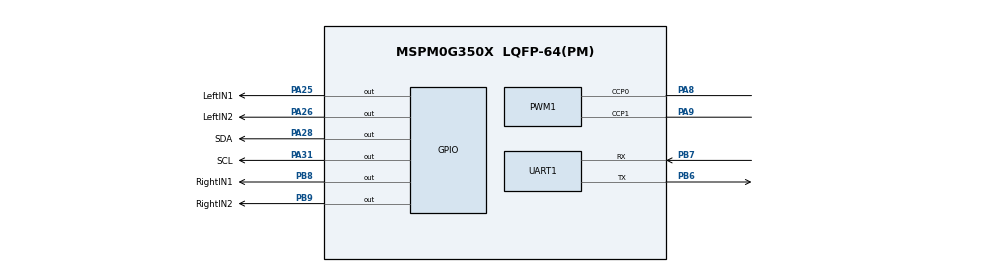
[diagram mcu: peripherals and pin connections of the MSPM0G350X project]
/**
 * These arguments were used when this file was generated. They will be automatically applied on subsequent loads
 * via the GUI or CLI. Run CLI with '--help' for additional information on how to override these arguments.
 * @cliArgs --device "MSPM0G350X" --package "LQFP-64(PM)" --part "Default" --product "mspm0_sdk@2.01.00.03"
 * @versions {"tool":"1.20.0+3587"}
 */

/**
 * Import the modules used in this configuration.
 */
const GPIO    = scripting.addModule("/ti/driverlib/GPIO", {}, false);
const GPIO1   = GPIO.addInstance();
const GPIO2   = GPIO.addInstance();
const PWM     = scripting.addModule("/ti/driverlib/PWM", {}, false);
const PWM1    = PWM.addInstance();
const SYSCTL  = scripting.addModule("/ti/driverlib/SYSCTL");
const SYSTICK = scripting.addModule("/ti/driverlib/SYSTICK");
const TIMER   = scripting.addModule("/ti/driverlib/TIMER", {}, false);
const TIMER1  = TIMER.addInstance();
const UART    = scripting.addModule("/ti/driverlib/UART", {}, false);
const UART1   = UART.addInstance();

/**
 * Write custom configuration values to the imported modules.
 */
const gate7  = system.clockTree["MFCLKGATE"];
gate7.enable = true;

GPIO1.$name                         = "OLED";
GPIO1.port                          = "PORTA";
GPIO1.associatedPins.create(2);
GPIO1.associatedPins[0].$name       = "SCL";
GPIO1.associatedPins[0].assignedPin = "31";
GPIO1.associatedPins[0].pin.$assign = "PA31";
GPIO1.associatedPins[1].$name       = "SDA";
GPIO1.associatedPins[1].assignedPin = "28";
GPIO1.associatedPins[1].pin.$assign = "PA28";

const Board = scripting.addModule("/ti/driverlib/Board", {}, false);

GPIO2.$name                          = "MotorIN";
GPIO2.associatedPins.create(4);
GPIO2.associatedPins[0].$name        = "LeftIN1";
GPIO2.associatedPins[0].assignedPort = "PORTA";
GPIO2.associatedPins[0].assignedPin  = "25";
GPIO2.associatedPins[0].pin.$assign  = "PA25";
GPIO2.associatedPins[1].$name        = "LeftIN2";
GPIO2.associatedPins[1].assignedPort = "PORTA";
GPIO2.associatedPins[1].assignedPin  = "26";
GPIO2.associatedPins[1].pin.$assign  = "PA26";
GPIO2.associatedPins[2].$name        = "RightIN1";
GPIO2.associatedPins[2].assignedPort = "PORTB";
GPIO2.associatedPins[2].assignedPin  = "8";
GPIO2.associatedPins[2].pin.$assign  = "PB8";
GPIO2.associatedPins[3].$name        = "RightIN2";
GPIO2.associatedPins[3].assignedPort = "PORTB";
GPIO2.associatedPins[3].assignedPin  = "9";
GPIO2.associatedPins[3].pin.$assign  = "PB9";

PWM1.clockDivider                       = 8;
PWM1.timerCount                         = 7200;
PWM1.timerStartTimer                    = true;
PWM1.$name                              = "MotorPWM";
PWM1.pwmMode                            = "EDGE_ALIGN_UP";
PWM1.peripheral.$assign                 = "TIMA0";
PWM1.peripheral.ccp0Pin.$assign         = "PA8";
PWM1.peripheral.ccp1Pin.$assign         = "PA9";
PWM1.PWM_CHANNEL_0.$name                = "ti_driverlib_pwm_PWMTimerCC0";
PWM1.PWM_CHANNEL_1.$name                = "ti_driverlib_pwm_PWMTimerCC1";
PWM1.ccp0PinConfig.$name                = "ti_driverlib_gpio_GPIOPinGeneric0";
PWM1.ccp0PinConfig.direction            = scripting.forceWrite("OUTPUT");
PWM1.ccp0PinConfig.hideOutputInversion  = scripting.forceWrite(false);
PWM1.ccp0PinConfig.onlyInternalResistor = scripting.forceWrite(false);
PWM1.ccp0PinConfig.passedPeripheralType = scripting.forceWrite("Digital");
PWM1.ccp1PinConfig.$name                = "ti_driverlib_gpio_GPIOPinGeneric1";
PWM1.ccp1PinConfig.direction            = scripting.forceWrite("OUTPUT");
PWM1.ccp1PinConfig.hideOutputInversion  = scripting.forceWrite(false);
PWM1.ccp1PinConfig.onlyInternalResistor = scripting.forceWrite(false);
PWM1.ccp1PinConfig.passedPeripheralType = scripting.forceWrite("Digital");

SYSCTL.forceDefaultClkConfig = true;
SYSCTL.clockTreeEn           = true;

SYSTICK.periodEnable      = true;
SYSTICK.period            = 32000;
SYSTICK.interruptEnable   = true;
SYSTICK.interruptPriority = "0";
SYSTICK.systickEnable     = true;

TIMER1.$name              = "Timer";
TIMER1.timerClkDiv        = 8;
TIMER1.timerClkPrescale   = 100;
TIMER1.timerMode          = "PERIODIC";
TIMER1.timerPeriod        = "10 ms";
TIMER1.timerStartTimer    = true;
TIMER1.interrupts         = ["ZERO"];
TIMER1.peripheral.$assign = "TIMG0";

UART1.$name                            = "OpenMVSerial";
UART1.uartClkSrc                       = "MFCLK";
UART1.enabledInterrupts                = ["RX"];
UART1.interruptPriority                = "1";
UART1.peripheral.$assign               = "UART1";
UART1.peripheral.rxPin.$assign         = "PB7";
UART1.peripheral.txPin.$assign         = "PB6";
UART1.txPinConfig.$name                = "ti_driverlib_gpio_GPIOPinGeneric2";
UART1.txPinConfig.direction            = scripting.forceWrite("OUTPUT");
UART1.txPinConfig.hideOutputInversion  = scripting.forceWrite(false);
UART1.txPinConfig.onlyInternalResistor = scripting.forceWrite(false);
UART1.txPinConfig.passedPeripheralType = scripting.forceWrite("Digital");
UART1.rxPinConfig.$name                = "ti_driverlib_gpio_GPIOPinGeneric3";
UART1.rxPinConfig.hideOutputInversion  = scripting.forceWrite(false);
UART1.rxPinConfig.onlyInternalResistor = scripting.forceWrite(false);
UART1.rxPinConfig.passedPeripheralType = scripting.forceWrite("Digital");

/**
 * Pinmux solution for unlocked pins/peripherals. This ensures that minor changes to the automatic solver in a future
 * version of the tool will not impact the pinmux you originally saw.  These lines can be completely deleted in order to
 * re-solve from scratch.
 */
Board.peripheral.$suggestSolution          = "DEBUGSS";
Board.peripheral.swclkPin.$suggestSolution = "PA20";
Board.peripheral.swdioPin.$suggestSolution = "PA19";
